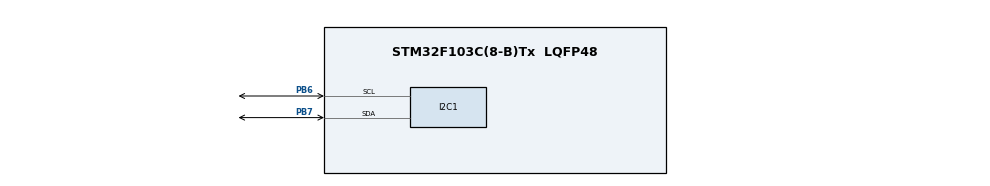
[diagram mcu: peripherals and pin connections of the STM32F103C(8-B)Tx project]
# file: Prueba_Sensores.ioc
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Mcu.Family=STM32F1
Mcu.Name=STM32F103C(8-B)Tx
Mcu.Package=LQFP48
NVIC.PriorityGroup=NVIC_PRIORITYGROUP_4
PA13.Mode=Serial_Wire
PA13.Signal=SYS_JTMS-SWDIO
PA14.Mode=Serial_Wire
PA14.Signal=SYS_JTCK-SWCLK
PB6.Mode=I2C
PB6.Signal=I2C1_SCL
PB7.Mode=I2C
PB7.Signal=I2C1_SDA
ProjectManager.HeapSize=0x200
ProjectManager.StackSize=0x400
ProjectManager.TargetToolchain=STM32CubeIDE
RCC.APB1Freq_Value=8000000
RCC.APB2Freq_Value=8000000
board=custom

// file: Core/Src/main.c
/* USER CODE BEGIN Header */
/**
  ******************************************************************************
  * @file           : main.c
  * @brief          : Main program body
  ******************************************************************************
  * @attention
  *
  * Copyright (c) 2026 STMicroelectronics.
  * All rights reserved.
  *
  * This software is licensed under terms that can be found in the LICENSE file
  * in the root directory of this software component.
  * If no LICENSE file comes with this software, it is provided AS-IS.
  *
  ******************************************************************************
  */
/* USER CODE END Header */
#include "main.h"

/* USER CODE BEGIN Includes */
#include <stdio.h>
#include <math.h>          // Crucial para la función pow()
#include "ssd1306.h"
#include "ssd1306_fonts.h"
#include "bmp280.h"        // Tu librería del sensor de presión
/* USER CODE END Includes */

I2C_HandleTypeDef hi2c1;

/* USER CODE BEGIN PV */
// --- Variables del BMP280 ---
BMP280_HandleTypedef bmp280;
const float PRESION_NIVEL_MAR = 101325.0f;
float temperatura, presion_Pa, humedad, altitud_m;

// --- Variables del MPU6050 ---
// Variables crudas (enteros de 16 bits)
int16_t Accel_X_RAW, Accel_Y_RAW, Accel_Z_RAW;
int16_t Gyro_X_RAW, Gyro_Y_RAW, Gyro_Z_RAW;

// Variables finales convertidas (decimales)
float Ax, Ay, Az;
float Gx, Gy, Gz;
/* USER CODE END PV */

void SystemClock_Config(void);
static void MX_GPIO_Init(void);
static void MX_I2C1_Init(void);
void Error_Handler(void);

int main(void)
{

  /* MCU Configuration--------------------------------------------------------*/

  /* Reset of all peripherals, Initializes the Flash interface and the Systick. */
  HAL_Init();

  /* Configure the system clock */
  SystemClock_Config();

  /* Initialize all configured peripherals */
  MX_GPIO_Init();
  MX_I2C1_Init();

  /* USER CODE BEGIN 2 */

    // 1. Iniciar Pantalla
    ssd1306_Init();
    ssd1306_Fill(Black);
    ssd1306_SetCursor(5, 25);
    ssd1306_WriteString("Iniciando...", Font_7x10, White);
    ssd1306_UpdateScreen();

    // 2. Iniciar BMP280
    bmp280.i2c = &hi2c1;
    bmp280.addr = BMP280_I2C_ADDRESS_0;
    bmp280_params_t params;
    bmp280_init_default_params(&params);
    bmp280_init(&bmp280, &params);

    // 3. Iniciar MPU6050
    ssd1306_Init();
    ssd1306_Fill(Black);
    ssd1306_SetCursor(5, 25);
    ssd1306_WriteString("Iniciando MPU...", Font_7x10, White);
    ssd1306_UpdateScreen();
    HAL_Delay(1000);

    // 2. Despertar al MPU6050 (Por defecto inicia "dormido")
    // Escribimos un 0x00 en el registro de Power Management (0x6B)
    uint8_t Data = 0x00;
    HAL_I2C_Mem_Write(&hi2c1, 0x68<<1, 0x6B, 1, &Data, 1, 1000);

    // Nota: Al despertar sin configurar nada más, el MPU6050 queda con
    // sensibilidades por defecto: +/- 2G (Acelerómetro) y +/- 250°/s (Giroscopio).

    HAL_Delay(1000); // Pausa para que todo se estabilice

    /* USER CODE END 2 */

  /* Infinite loop */
  while (1)
  {

	  /* USER CODE BEGIN 3 */
	    while (1)
	    {
	        char buffer_oled[64];

	        // --- 1. LEER BMP280 ---
	        if (bmp280_read_float(&bmp280, &temperatura, &presion_Pa, &humedad)) {
	            altitud_m = 44330.0f * (1.0f - pow((presion_Pa / PRESION_NIVEL_MAR), 0.1902949f));
	        }

	        // --- 2. LEER MPU6050 ---
	        // --- 2. LEER MPU6050 ---
	              uint8_t Data[14];

	              // Leer 14 bytes desde el registro 0x3B (ACCEL_XOUT_H)
	              HAL_I2C_Mem_Read(&hi2c1, 0xD0, 0x3B, 1, Data, 14, 1000);

	              // Ensamblar los bytes altos y bajos en enteros de 16 bits
	              Accel_X_RAW = (int16_t)(Data[0] << 8 | Data[1]);
	              Accel_Y_RAW = (int16_t)(Data[2] << 8 | Data[3]);
	              Accel_Z_RAW = (int16_t)(Data[4] << 8 | Data[5]);

	              Gyro_X_RAW = (int16_t)(Data[8] << 8 | Data[9]);
	              Gyro_Y_RAW = (int16_t)(Data[10] << 8 | Data[11]);
	              Gyro_Z_RAW = (int16_t)(Data[12] << 8 | Data[13]);

	              // Convertir a valores físicos (con decimales)
	              // Divisor 16384.0 para el acelerómetro (rango +/- 2g)
	              Ax = Accel_X_RAW / 16384.0f;
	              Ay = Accel_Y_RAW / 16384.0f;
	              Az = Accel_Z_RAW / 16384.0f;

	              // Divisor 131.0 para el giroscopio (rango +/- 250 grados/s)
	              Gx = Gyro_X_RAW / 131.0f;
	              Gy = Gyro_Y_RAW / 131.0f;
	              Gz = Gyro_Z_RAW / 131.0f;

	        // --- 3. MOSTRAR EN OLED ---
	        ssd1306_Fill(Black);

	        // Fila 1: Altura y Temperatura (BMP280)
	        sprintf(buffer_oled, "Alt:%.1fm T:%.0fC", altitud_m, temperatura);
	        ssd1306_SetCursor(2, 2);
	        ssd1306_WriteString(buffer_oled, Font_7x10, White);

	        // Separador visual
	        ssd1306_Line(0, 15, 128, 15, White);

	        // Fila 2: Acelerómetro X e Y
	        sprintf(buffer_oled, "Ax:%.2f Ay:%.2f", Ax, Ay); // Reemplaza Ax y Ay por tus variables
	        ssd1306_SetCursor(2, 20);
	        ssd1306_WriteString(buffer_oled, Font_7x10, White);

	        // Fila 3: Acelerómetro Z
	        sprintf(buffer_oled, "Az:%.2f Gs", Az); // Reemplaza Az por tu variable
	        ssd1306_SetCursor(2, 35);
	        ssd1306_WriteString(buffer_oled, Font_7x10, White);

	        // Fila 4: Giroscopio (resumen)
	        sprintf(buffer_oled, "Gx:%.0f Gy:%.0f", Gx, Gy); // Reemplaza Gx y Gy por tus variables
	        ssd1306_SetCursor(2, 50);
	        ssd1306_WriteString(buffer_oled, Font_7x10, White);

	        ssd1306_UpdateScreen();

	        // Un delay corto para que la pantalla se sienta fluida
	        HAL_Delay(100);
	    }
	    /* USER CODE END 3 */
  }
}

void SystemClock_Config(void)
{
  RCC_OscInitTypeDef RCC_OscInitStruct = {0};
  RCC_ClkInitTypeDef RCC_ClkInitStruct = {0};

  /** Initializes the RCC Oscillators according to the specified parameters
  * in the RCC_OscInitTypeDef structure.
  */
  RCC_OscInitStruct.OscillatorType = RCC_OSCILLATORTYPE_HSI;
  RCC_OscInitStruct.HSIState = RCC_HSI_ON;
  RCC_OscInitStruct.HSICalibrationValue = RCC_HSICALIBRATION_DEFAULT;
  RCC_OscInitStruct.PLL.PLLState = RCC_PLL_NONE;
  if (HAL_RCC_OscConfig(&RCC_OscInitStruct) != HAL_OK)
  {
    Error_Handler();
  }

  /** Initializes the CPU, AHB and APB buses clocks
  */
  RCC_ClkInitStruct.ClockType = RCC_CLOCKTYPE_HCLK|RCC_CLOCKTYPE_SYSCLK
                              |RCC_CLOCKTYPE_PCLK1|RCC_CLOCKTYPE_PCLK2;
  RCC_ClkInitStruct.SYSCLKSource = RCC_SYSCLKSOURCE_HSI;
  RCC_ClkInitStruct.AHBCLKDivider = RCC_SYSCLK_DIV1;
  RCC_ClkInitStruct.APB1CLKDivider = RCC_HCLK_DIV1;
  RCC_ClkInitStruct.APB2CLKDivider = RCC_HCLK_DIV1;

  if (HAL_RCC_ClockConfig(&RCC_ClkInitStruct, FLASH_LATENCY_0) != HAL_OK)
  {
    Error_Handler();
  }
}

static void MX_I2C1_Init(void)
{

  hi2c1.Instance = I2C1;
  hi2c1.Init.ClockSpeed = 100000;
  hi2c1.Init.DutyCycle = I2C_DUTYCYCLE_2;
  hi2c1.Init.OwnAddress1 = 0;
  hi2c1.Init.AddressingMode = I2C_ADDRESSINGMODE_7BIT;
  hi2c1.Init.DualAddressMode = I2C_DUALADDRESS_DISABLE;
  hi2c1.Init.OwnAddress2 = 0;
  hi2c1.Init.GeneralCallMode = I2C_GENERALCALL_DISABLE;
  hi2c1.Init.NoStretchMode = I2C_NOSTRETCH_DISABLE;
  if (HAL_I2C_Init(&hi2c1) != HAL_OK)
  {
    Error_Handler();
  }

}

static void MX_GPIO_Init(void)
{

  /* GPIO Ports Clock Enable */
  __HAL_RCC_GPIOA_CLK_ENABLE();
  __HAL_RCC_GPIOB_CLK_ENABLE();

}

void Error_Handler(void)
{
  __disable_irq();
  while (1)
  {
  }
}
